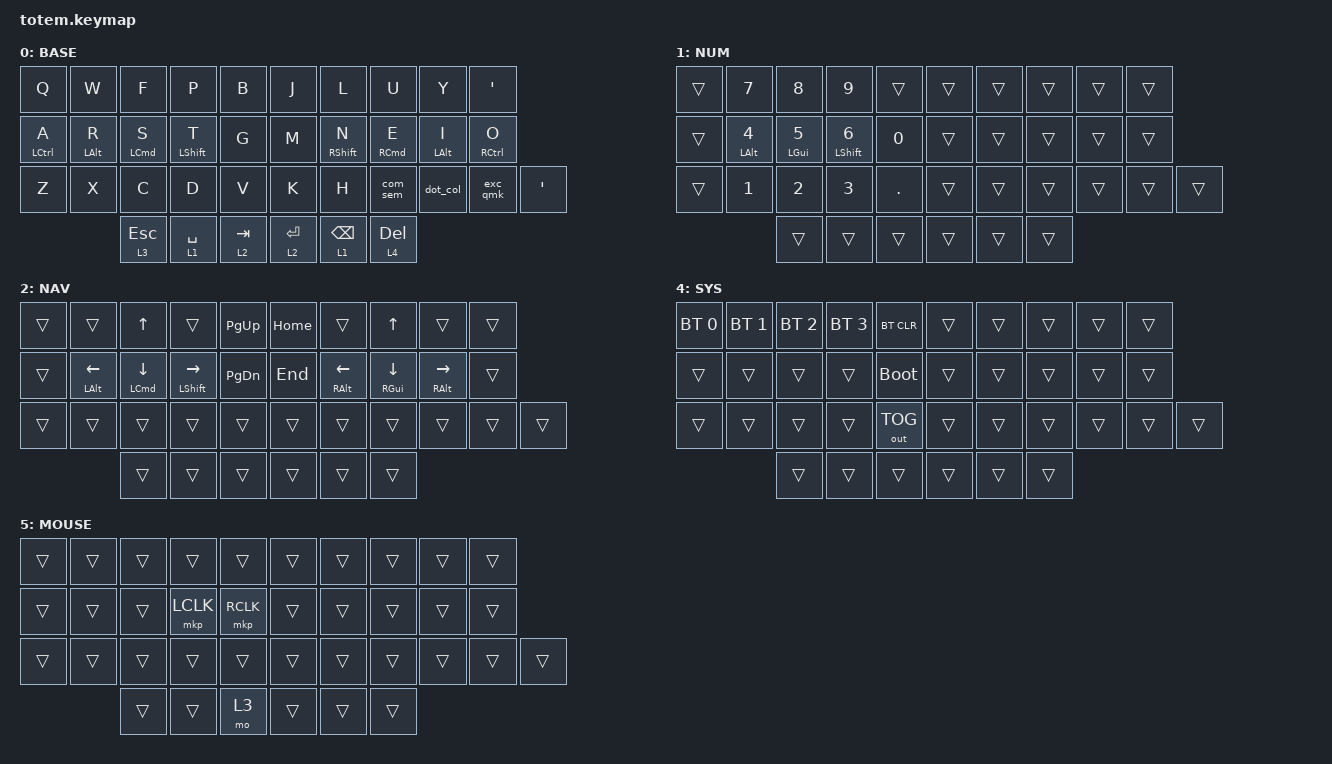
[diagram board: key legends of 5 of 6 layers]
#include <behaviors.dtsi>
#include <behaviors/num_word.dtsi>
#include <dt-bindings/zmk/bt.h>
#include <dt-bindings/zmk/keys.h>
#include <dt-bindings/zmk/outputs.h>
#include <dt-bindings/zmk/pointing.h>

#define BASE 0
#define NAV  1
#define NUM  2
#define ADJ  3
#define TVP1 4
#define TVP2 5

#define REQUIRE_PRIOR_IDLE_MS 150
#define QUICK_TAP_MS 175
#define SMART_NUM &smart_num NUM 0
#define CANCEL    &kp K_CANCEL

/ {
    behaviors {
        hml: hml {
            compatible = "zmk,behavior-hold-tap";
            label = "HML";
            bindings = <&kp>, <&kp>;

            #binding-cells = <2>;
            tapping-term-ms = <230>;
            quick-tap-ms = <175>;
            flavor = "tap-preferred";
            hold-trigger-key-positions = <5 6 7 8 9 15 16 17 18 19 26 27 28 29 30 31 35 36 37>;
            require-prior-idle-ms = <350>;
        };

        hmr: hmr {
            compatible = "zmk,behavior-hold-tap";
            label = "HMR";
            bindings = <&kp>, <&kp>;

            #binding-cells = <2>;
            tapping-term-ms = <230>;
            quick-tap-ms = <175>;
            flavor = "tap-preferred";
            hold-trigger-key-positions = <0 1 2 3 4 10 11 12 13 14 20 21 22 23 24 25 32 33 34>;
            require-prior-idle-ms = <350>;
        };

        copy_cut: copy_cut {
            compatible = "zmk,behavior-tap-dance";
            label = "COPY_CUT";
            #binding-cells = <0>;
            bindings = <&kp LC(C)>, <&kp LC(X)>;
        };

        com_sem: com_sem {
            compatible = "zmk,behavior-mod-morph";
            label = "COM_SEM";
            bindings = <&kp COMMA>, <&kp SEMICOLON>;

            #binding-cells = <0>;
            mods = <(MOD_LSFT|MOD_RSFT)>;
        };

        dot_col: dot_col {
            compatible = "zmk,behavior-mod-morph";
            label = "DOT_COL";
            bindings = <&kp PERIOD>, <&kp COLON>;

            #binding-cells = <0>;
            mods = <(MOD_LSFT|MOD_RSFT)>;
        };

        exc_qmk: exc_qmk {
            compatible = "zmk,behavior-mod-morph";
            label = "EXC_QMK";
            bindings = <&kp EXCLAMATION>, <&kp QUESTION>;

            #binding-cells = <0>;
            mods = <(MOD_LSFT|MOD_RSFT)>;
        };

        bac_del: bac_del {
            compatible = "zmk,behavior-mod-morph";
            label = "BAC_DEL";
            bindings = <&kp BACKSPACE>, <&kp DELETE>;

            #binding-cells = <0>;
            mods = <(MOD_LSFT|MOD_RSFT)>;
            keep-mods = <(MOD_RSFT)>;
        };

        hmsl: hmsl {
            compatible = "zmk,behavior-hold-tap";
            label = "HMSL";
            bindings = <&kp>, <&kp>;

            #binding-cells = <2>;
            tapping-term-ms = <220>;
            quick-tap-ms = <175>;
            flavor = "hold-preferred";
            hold-trigger-key-positions = <5 6 7 8 9 15 16 17 18 19 26 27 28 29 30 31 35 36 37>;
            require-prior-idle-ms = <140>;
        };

        hmsr: hmsr {
            compatible = "zmk,behavior-hold-tap";
            label = "HMSR";
            bindings = <&kp>, <&kp>;

            #binding-cells = <2>;
            tapping-term-ms = <220>;
            quick-tap-ms = <175>;
            flavor = "hold-preferred";
            hold-trigger-key-positions = <0 1 2 3 4 10 11 12 13 14 20 21 22 23 24 25 32 33 34>;
            require-prior-idle-ms = <140>;
        };

        lpar_less: lpar_less {
            compatible = "zmk,behavior-mod-morph";
            label = "LPAR_LESS";
            bindings = <&kp LEFT_PARENTHESIS>, <&kp LESS_THAN>;

            #binding-cells = <0>;
            mods = <(MOD_LSFT|MOD_RSFT)>;
        };

        rpar_greater: rpar_greater {
            compatible = "zmk,behavior-mod-morph";
            label = "RPAR_GREATER";
            bindings = <&kp RIGHT_PARENTHESIS>, <&kp GREATER_THAN>;

            #binding-cells = <0>;
            mods = <(MOD_LSFT|MOD_RSFT)>;
        };

        slash_bslash: slash_bslash {
            compatible = "zmk,behavior-mod-morph";
            label = "SLASH_BSLASH";
            bindings = <&kp SLASH>, <&kp BACKSLASH>;

            #binding-cells = <0>;
            mods = <(MOD_LSFT|MOD_RSFT)>;
        };

        ltm: ltm {
            compatible = "zmk,behavior-hold-tap";
            label = "LTM";
            bindings = <&mo>, <&kp>;

            #binding-cells = <2>;
            tapping-term-ms = <200>;
            quick-tap-ms = <175>;
            flavor = "balanced";
            hold-trigger-on-release;
            require-prior-idle-ms = <100>;
        };

        ltm2: ltm2 {
            compatible = "zmk,behavior-hold-tap";
            label = "LTM2";
            bindings = <&mo>, <&bac_del>;

            #binding-cells = <2>;
            tapping-term-ms = <280>;
            quick-tap-ms = <175>;
            flavor = "balanced";
            hold-trigger-on-release;
            require-prior-idle-ms = <150>;
        };

        num_dance: num_dance {
            compatible = "zmk,behavior-tap-dance";
            label = "ZMK_TAP_DANCE";
            #binding-cells = <0>;
            bindings = <&bac_del>, <&num_word 2>;
        };

        smart_num: smart_num {
            compatible = "zmk,behavior-hold-tap";
            tapping-term-ms = <200>;
            quick-tap-ms = <175>;
            flavor = "balanced";
            #binding-cells = <2>;
            bindings = <&mo>, <&num_dance>;
        };
    };

    combos {
        compatible = "zmk,combos";

        caps_word {
            bindings = <&caps_word>;
            key-positions = <13 16>;
        };

        esc_combo {
            bindings = <&gresc>;
            key-positions = <0 1>;
        };

        find_combos {
            bindings = <&kp LS(F)>;
            key-positions = <21 2>;
        };

        save_combos {
            bindings = <&kp LC(S)>;
            key-positions = <21 12>;
        };

        copy_combos {
            bindings = <&copy_cut>;
            key-positions = <21 23>;
        };

        all_combos {
            bindings = <&kp LC(A)>;
            key-positions = <21 10>;
        };

        paste_combos {
            bindings = <&kp LC(V)>;
            key-positions = <21 25>;
        };

        wm12 {
            bindings = <&kp LA(LG(E))>;
            key-positions = <5 15>;
            layers = <3>;
        };

        wm_23 {
            bindings = <&kp LA(LG(T))>;
            key-positions = <15 26>;
            layers = <3>;
        };

        l_par {
            bindings = <&lpar_less>;
            key-positions = <16 17>;
            require-prior-idle-ms = <200>;
        };

        r_par {
            bindings = <&rpar_greater>;
            key-positions = <17 18>;
            require-prior-idle-ms = <200>;
        };

        l_br {
            bindings = <&kp LEFT_BRACKET>;
            key-positions = <27 28>;
            require-prior-idle-ms = <200>;
        };

        r_br {
            bindings = <&kp RIGHT_BRACKET>;
            key-positions = <28 29>;
            require-prior-idle-ms = <200>;
        };

        plus {
            bindings = <&kp KP_PLUS>;
            key-positions = <6 16>;
        };

        minus {
            bindings = <&kp MINUS>;
            key-positions = <16 27>;
        };

        star {
            bindings = <&kp ASTERISK>;
            key-positions = <7 17>;
        };

        spl {
            bindings = <&slash_bslash>;
            key-positions = <17 28>;
        };

        and {
            bindings = <&kp AMPERSAND>;
            key-positions = <5 15>;
        };

        or {
            bindings = <&kp PIPE>;
            key-positions = <15 26>;
        };

        equ {
            bindings = <&kp EQUAL>;
            key-positions = <8 18>;
        };

        under_sc {
            bindings = <&kp UNDER>;
            key-positions = <18 29>;
        };

        grave_combos {
            bindings = <&kp GRAVE>;
            key-positions = <13 24>;
        };

        at_combos {
            bindings = <&kp AT>;
            key-positions = <1 11>;
        };

        hash_combos {
            bindings = <&kp HASH>;
            key-positions = <2 12>;
        };

        dollor_combos {
            bindings = <&kp DOLLAR>;
            key-positions = <3 13>;
        };

        percent_combos {
            bindings = <&kp PERCENT>;
            key-positions = <11 22>;
        };

        hat_combos {
            bindings = <&kp CARET>;
            key-positions = <12 23>;
        };

        screenshot {
            bindings = <&kp LG(LC(LS(N4)))>;
            key-positions = <11 12 13 33>;
        };

        undo_combos {
            bindings = <&kp LC(Z)>;
            key-positions = <21 22>;
        };

        cap {
            bindings = <&caps_word>;
            key-positions = <20 31>;
        };

        func_spa1 {
            bindings = <&kp LC(SPACE)>;
            key-positions = <33 19>;
        };

        func_spa2 {
            bindings = <&kp LC(SPACE)>;
            key-positions = <10 33>;
        };
    };

    macros {
        accent: acute {
            compatible = "zmk,behavior-macro-two-param";
            #binding-cells = <2>;
            bindings =
                <&macro_tap>,
                <&macro_param_1to1 &kp MACRO_PLACEHOLDER>,
                <&macro_tap>,
                <&macro_param_2to1 &kp MACRO_PLACEHOLDER>;

            label = "ACUTE";
        };

        colon_macro: colon_macro {
            compatible = "zmk,behavior-macro";
            #binding-cells = <0>;
            bindings
                = <&macro_release &kp LSHFT &kp RSHFT>
                , <&macro_tap &kp LS(SEMI)>
                ;
        };
    };

    keymap {
        compatible = "zmk,keymap";

        base_layer {
            label = "BASE";
            bindings = <
&kp Q         &kp W            &kp F                &kp P          &kp B         &kp J         &kp L             &kp U                 &kp Y        &kp SINGLE_QUOTE
&hml LCTRL A  &hml LEFT_ALT R  &hml LEFT_COMMAND S  &hmsl LSHFT T  &kp G         &kp M         &hmsr RSHFT N     &hmr RIGHT_COMMAND E  &hmr LALT I  &hmr RCTRL O
&kp Z         &kp X            &kp C                &kp D          &kp V         &kp K         &kp H             &com_sem              &dot_col     &exc_qmk          &kp SINGLE_QUOTE
                                   &ltm 3 ESCAPE        &ltm 1 SPACE   &ltm 2 TAB    &ltm 2 ENTER  &ltm 1 BACKSPACE  &ltm 4 DELETE
            >;
        };

        num_layer {
            label = "NUM";
            bindings = <
&trans  &kp N7            &kp N8            &kp N9          &trans     &trans  &trans  &trans  &trans  &trans
&trans  &hml LEFT_ALT N4  &hml LEFT_GUI N5  &hml LSHIFT N6  &kp N0     &trans  &trans  &trans  &trans  &trans
&trans  &kp N1            &kp N2            &kp N3          &kp DOT    &trans  &trans  &trans  &trans  &trans  &trans
                                   &trans            &trans          &trans     &trans  &trans  &trans
            >;
        };

        nav_layer {
            label = "NAV";
            bindings = <
&trans  &trans              &kp UP                  &trans             &kp PAGE_UP      &kp HOME  &trans               &kp UP          &trans           &trans
&trans  &hml LEFT_ALT LEFT  &hml LEFT_COMMAND DOWN  &hml LSHIFT RIGHT  &kp PAGE_DOWN    &kp END   &hmr RIGHT_ALT LEFT  &hmr RGUI DOWN  &hmr RALT RIGHT  &trans
&trans  &trans              &trans                  &trans             &trans           &trans    &trans               &trans          &trans           &trans  &trans
                                     &trans                  &trans             &trans           &trans    &trans               &trans
            >;
        };

        fn_layer {
            label = "FUN";
            bindings = <
&kp F12                &kp F7        &kp F8        &kp F9         &trans    &kp LA(LG(D))  &none                            &kp C_VOLUME_UP                   &none                &none
&hml LEFT_CONTROL F11  &hml LALT F4  &hml LGUI F5  &hml LSHFT F6  &trans    &kp LA(LG(F))  &hmr RIGHT_SHIFT LG(LEFT_ARROW)  &hmr RIGHT_COMMAND C_VOLUME_DOWN  &hmr LALT LG(RIGHT)  &kp RCTRL
&trans                 &kp F10       &kp F1        &kp F2         &kp F3    &kp LA(LG(G))  &kp LA(LG(LEFT))                 &kp C_MUTE                        &kp LA(LG(RIGHT))    &none
                                     &trans        &trans         &trans    &trans         &trans                           &trans
            >;
        };

        sys_layer {
            label = "SYS";
            bindings = <
&bt BT_SEL 0  &bt BT_SEL 1  &bt BT_SEL 2  &bt BT_SEL 3  &bt BT_CLR      &trans  &trans  &trans  &trans  &trans
&trans        &trans        &trans        &trans        &bootloader     &trans  &trans  &trans  &trans  &trans
&trans        &trans        &trans        &trans        &out OUT_TOG    &trans  &trans  &trans  &trans  &trans  &trans
                                     &trans        &trans        &trans          &trans  &trans  &trans
            >;
        };

        mouse {
            label = "MOUSE";
            bindings = <
&trans  &trans  &trans  &trans     &trans       &trans  &trans  &trans  &trans  &trans
&trans  &trans  &trans  &mkp LCLK  &mkp RCLK    &trans  &trans  &trans  &trans  &trans
&trans  &trans  &trans  &trans     &trans       &trans  &trans  &trans  &trans  &trans  &trans
                &trans  &trans     &mo 3        &trans  &trans  &trans
            >;
        };
    };
};
